# SYSCTRL_GENERAL_WKUP register map
Vendor: Texas Instruments
Peripheral module from a debugger description file (folder omap4430).
Registers are 32-bit, access per field, reset 0x0 unless marked. A register's access mark holds for its fields unless they carry their own. Offsets are as the file gives them; lines under a group give offsets from that group; [hi:lo] are bit positions; {n}, {i} and the like mark numbered series; 'fields as' and 'values as' point back to an identical list; <NAME> marks a mode.

## SYSCTRL_GENERAL_WKUP
0x00 CONTROL_GEN_WKUP_REVISION ro reset not defined — Control module revision identifier Access conditions. Read: unrestricted, Write: unrestricted
  [31:0] REVISION — IP Revision
0x04 CONTROL_GEN_WKUP_HWINFO ro — Information about the IP module hardware configuration that is, typically the module HDL generics (if any). Access conditions. Read: unrestricted, Write: unrestricted
  [31:0] IP_HWINFO — IP-module dependent
0x10 CONTROL_GEN_WKUP_SYSCONFIG reset 0x8 — Access conditions. Read: unrestricted, Write: unrestricted
  [3:2] IP_SYSCONFIG_IDLEMODE rw — Select the local clock-gating strategy0x2,0x3: Clock is automatically gated when there is no access to the Control Module through L4-interconnect .
    0=Clock is manually gated; 1=Clock is manually enabled
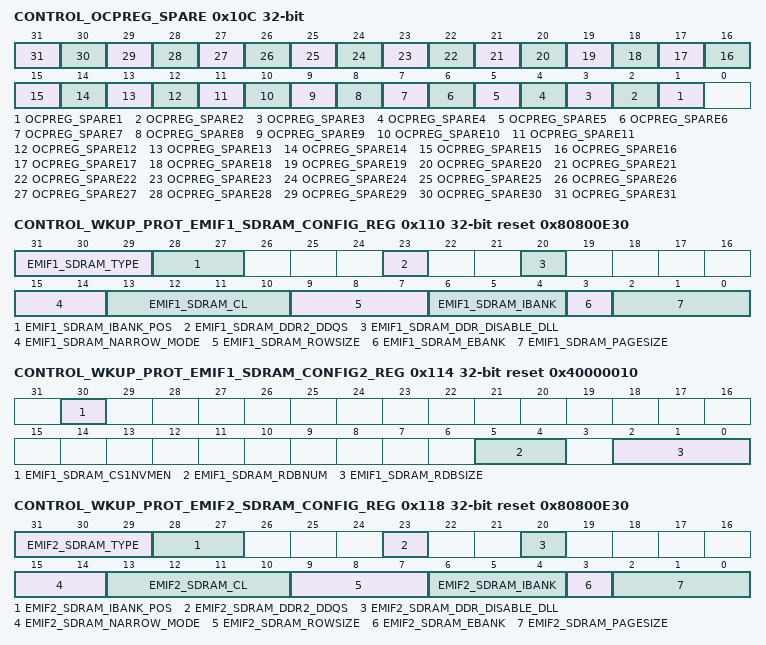
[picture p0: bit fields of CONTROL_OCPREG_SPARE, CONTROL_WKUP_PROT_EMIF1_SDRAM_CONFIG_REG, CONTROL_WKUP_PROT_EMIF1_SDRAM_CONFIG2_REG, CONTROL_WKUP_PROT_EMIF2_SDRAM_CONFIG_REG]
0x10C CONTROL_OCPREG_SPARE rw — Spare Register Access conditions. Read: unrestricted, Write: unrestricted
  [n] OCPREG_SPARE{n} (n=1..31) — Spare register {n}
0x110 CONTROL_WKUP_PROT_EMIF1_SDRAM_CONFIG_REG reset 0x80800E30 — Protection EMIF1 SDRAM configuration register 1 Access conditions. Read: unrestricted, Write: unrestricted
  [31:29] EMIF1_SDRAM_TYPE rw — SDRAM type selection:Set to 0x4 for LPDDR2-S4. . Set to 0x5 for LPDDR2-S2. . All other values are reserved. .
  [28:27] EMIF1_SDRAM_IBANK_POS rw — Internal bank position:Set to 0x0 to assign internal bank address bits from the L3 address as shown in, 64-Byte Linear Read Starting at Address 0x0, and , 64-Byte Linear Read Starting at Address 0x8 (LPDDR2-S2), in , Memory Subsystem. . Set to 0x1, 0x2, or 0x3 to assign internal bank address bits from the L3 address as shown in, 64-Byte Linear Read Starting at Address 0x8 (LPDDR2-S4), , 64-Byte Linear Read Starting at Address 0x10, and , 64-Byte Linear Read Starting at Address 0x18, in , Memory Subsystem. .
  [23] EMIF1_SDRAM_DDR2_DDQS rw — DDR2 differential DQS enable:Set to 0 for single ended DQS. . Set to 1 for differential DQS. . This bit is only for DDR2 mode; because the device supports LPDDR2, this bit is don’t care. .
  [20] EMIF1_SDRAM_DDR_DISABLE_DLL rw — Disable DLL select:Set to 0x0 to enable DLL inside SDRAM. . Set to 0x1 to disable DLL inside SDRAM. .
  [15:14] EMIF1_SDRAM_NARROW_MODE rw — SDRAM data bus width:Set to 0x0 for 64-bit width. . Set to 0x1 for 32-bit width. . Set to 0x2 for 16-bit width. . All other values are reserved. .
  [13:10] EMIF1_SDRAM_CL rw — CAS latency (RL latency). The value of this field defines the CAS latency to be used when accessing connected SDRAM devices:Supported for LPDDR2-SDRAM: . All other values are reserved. .
    {v}=CAS latency of {v} cycles (v=3..8)
  [9:7] EMIF1_SDRAM_ROWSIZE rw — Row size. Defines the number of row address bits of connected SDRAM devices:Set to 0x0 for 9 row bits. . Set to 0x1 for 10 row bits. . Set to 0x2 for 11 row bits. . Set to 0x3 for 12 row bits. . Set to 0x4 for 13 row bits. . Set to 0x5 for 14 row bits. . Set to 0x6 for 15 row bits. . Set to 0x7 for 16 row bits. . This field is used only when the ibank_pos field in the SDRAM Config register is set to 0x1, 0x2, or 0x3. .
  [6:4] EMIF1_SDRAM_IBANK rw — Internal bank setup. Defines number of banks inside connected SDRAM devices:Set to 0x0 for 1 bank. . Set to 0x1 for 2 banks. . Set to 0x2 for 4 banks. . Set to 0x3 for 8 banks. . All other values are reserved. .
  [3] EMIF1_SDRAM_EBANK rw — External CS setup. Defines whether SDRAM accesses will use 1 or 2 CS lines. Set to 0 to use pad_cs_o_n[0] only:Set to 0x0 to use only pad_cs_o_n[0]. . Set to 0x1 to use pad_cs_o_n[1:0]. . This bit is automatically set to 0 if either the cs0nvmen or cs1nvmen field in the LPDDR2-NVM is set to 1. .
  [2:0] EMIF1_SDRAM_PAGESIZE rw — Page size. Defines the internal page size of the connected SDRAM devices:Set to 0x0 for 256-word page (8 column bits). . Set to 0x1 for 512-word page (9 column bits). . Set to 0x2 for 1024-word page (10 column bits). . Set to 0x3 for 2048-word page (11 column bits). . All other values are reserved. .
0x114 CONTROL_WKUP_PROT_EMIF1_SDRAM_CONFIG2_REG reset 0x40000010 — Protection EMIF1 SDRAM configuration register 2 Access conditions. Read: unrestricted, Write: unrestricted
  [30] EMIF1_SDRAM_CS1NVMEN rw — CS1 LPDDR2-NVM enable:Set to 0x1 if LPDDR2-NVM is connected to CS1. . This bit is automatically set to 0x0 if the sdram_type field in the SDRAM Config register is not set to LPDDR2. .
  [5:4] EMIF1_SDRAM_RDBNUM rw — Row buffer setup. Defines the number of row buffers inside the connected LPDDR2-NVM devices:Set to 0x0 for 1 row buffer. . Set to 0x1 for 2 row buffers. . Set to 0x2 for 4 row buffers. . Set to 0x3 for 8 row buffers. . All other values are reserved. .
  [2:0] EMIF1_SDRAM_RDBSIZE rw — Row data buffer size. Defines the row data buffer size of connected LPDDR2-NVM devices:Set to 0x0 for 32 bytes. . Set to 0x1 for 64 bytes. . Set to 0x2 for 128 bytes. . Set to 0x3 for 256 bytes. . Set to 0x4 for 512 bytes. . Set to 0x5 for 1024 bytes. . Set to 0x6 for 2048 bytes. . Set to 0x7 for 4096 bytes. .
0x118 CONTROL_WKUP_PROT_EMIF2_SDRAM_CONFIG_REG reset 0x80800E30 — Protection EMIF2 SDRAM configuration register 1 Access conditions. Read: unrestricted, Write: unrestricted
  [31:29] EMIF2_SDRAM_TYPE rw — SDRAM type selection:Set to 0x4 for LPDDR2-S4. . Set to 0x5 for LPDDR2-S2. . All other values are reserved. .
  [28:27] EMIF2_SDRAM_IBANK_POS rw — Internal bank position:Set to 0x0 to assign internal bank address bits from the L3 address as shown in, 64-Byte Linear Read Starting at Address 0x0, and , 64-Byte Linear Read Starting at Address 0x8 (LPDDR2-S2), in , Memory Subsystem. . Set to 0x1, 0x2, or 0x3 to assign internal bank address bits from the L3 address as shown in, 64-Byte Linear Read Starting at Address 0x8 (LPDDR2-S4), , 64-Byte Linear Read Starting at Address 0x10, and , 64-Byte Linear Read Starting at Address 0x18, in , Memory Subsystem. .
  [23] EMIF2_SDRAM_DDR2_DDQS rw — DDR2 differential DQS enable:Set to 0 for single ended DQS. . Set to 1 for differential DQS. . This bit is only for DDR2 mode; because the device supports LPDDR2, this bit is don’t care. .
  [20] EMIF2_SDRAM_DDR_DISABLE_DLL rw — Disable DLL select:Set to 0x0 to enable DLL inside SDRAM. . Set to 0x1 to disable DLL inside SDRAM. .
  [15:14] EMIF2_SDRAM_NARROW_MODE rw — SDRAM data bus width:Set to 0x0 for 64-bit width. . Set to 0x1 for 32-bit width. . Set to 0x2 for 16-bit width. . All other values are reserved. .
  [13:10] EMIF2_SDRAM_CL rw — CAS latency (RL latency). The value of this field defines the CAS latency to be used when accessing connected SDRAM devices:Supported for LPDDR2-SDRAM: . All other values are reserved. .
    {v}=CAS latency of {v} cycles (v=3..8)
  [9:7] EMIF2_SDRAM_ROWSIZE rw — Row size. Defines the number of row address bits of connected SDRAM devices:Set to 0x0 for 9 row bits. . Set to 0x1 for 10 row bits. . Set to 0x2 for 11 row bits. . Set to 0x3 for 12 row bits. . Set to 0x4 for 13 row bits. . Set to 0x5 for 14 row bits. . Set to 0x6 for 15 row bits. . Set to 0x7 for 16 row bits. . This field is used only when the ibank_pos field in the SDRAM Config register is set to 0x1, 0x2, or 0x3. .
  [6:4] EMIF2_SDRAM_IBANK rw — Internal bank setup. Defines number of banks inside connected SDRAM devices:Set to 0x0 for 1 bank. . Set to 0x1 for 2 banks. . Set to 0x2 for 4 banks. . Set to 0x3 for 8 banks. . All other values are reserved. .
  [3] EMIF2_SDRAM_EBANK rw — External CS setup. Defines whether SDRAM accesses will use 1 or 2 CS lines. Set to 0 to use pad_cs_o_n[0] only:Set to 0x0 to use only pad_cs_o_n[0]. . Set to 0x1 to use pad_cs_o_n[1:0]. . This bit is automatically set to 0 if either the cs0nvmen or cs1nvmen field in the LPDDR2-NVM is set to 1. .
  [2:0] EMIF2_SDRAM_PAGESIZE rw — Page size. Defines the internal page size of the connected SDRAM devices:Set to 0x0 for 256-word page (8 column bits). . Set to 0x1 for 512-word page (9 column bits). . Set to 0x2 for 1024-word page (10 column bits). . Set to 0x3 for 2048-word page (11 column bits). . All other values are reserved. .
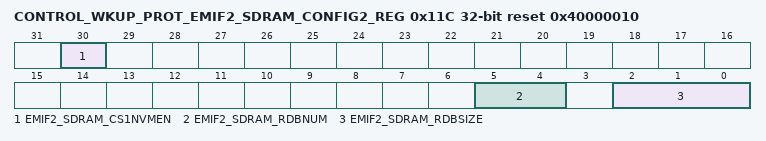
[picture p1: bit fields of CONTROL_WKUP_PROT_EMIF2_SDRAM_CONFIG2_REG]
0x11C CONTROL_WKUP_PROT_EMIF2_SDRAM_CONFIG2_REG reset 0x40000010 — Protection EMIF1 SDRAM configuration register 2 Access conditions. Read: unrestricted, Write: unrestricted
  [30] EMIF2_SDRAM_CS1NVMEN rw — CS1 LPDDR2-NVM enable:Set to 0x1 if LPDDR2-NVM is connected to CS1. . This bit is automatically set to 0x0 if the sdram_type field in the SDRAM Config register is not set to LPDDR2. .
  [5:4] EMIF2_SDRAM_RDBNUM rw — Row buffer setup. Defines the number of row buffers inside the connected LPDDR2-NVM devices:Set to 0x0 for 1 row buffer. . Set to 0x1 for 2 row buffers. . Set to 0x2 for 4 row buffers. . Set to 0x3 for 8 row buffers. . All other values are reserved. .
  [2:0] EMIF2_SDRAM_RDBSIZE rw — Row data buffer size. Defines the row data buffer size of connected LPDDR2-NVM devices:Set to 0x0 for 32 bytes. . Set to 0x1 for 64 bytes. . Set to 0x2 for 128 bytes. . Set to 0x3 for 256 bytes. . Set to 0x4 for 512 bytes. . Set to 0x5 for 1024 bytes. . Set to 0x6 for 2048 bytes. . Set to 0x7 for 4096 bytes. .
{0x460+4i} CONTROL_WKUP_CONF_DEBUG_SEL_TST_i_{i} (i=0..31) — Select mode for debug port Access conditions. Read: unrestricted, Write: unrestricted
  [0] MODE rw — Select one of the following signals:
    0=hwobs_int_prm_i; 1=hwobs_int_cm1_i
